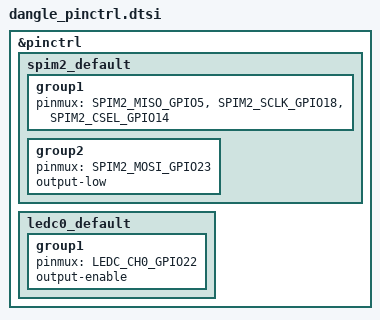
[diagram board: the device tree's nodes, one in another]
&pinctrl {
      spim2_default: spim2_default {
      		group1 {
      			pinmux = <SPIM2_MISO_GPIO5>,
      				 <SPIM2_SCLK_GPIO18>,
      				 <SPIM2_CSEL_GPIO14>;
      		};

      		group2 {
      			pinmux = <SPIM2_MOSI_GPIO23>;
      			output-low;
      		};

      	};

      	ledc0_default: ledc0_default {
      		group1 {
      			pinmux = <LEDC_CH0_GPIO22>;
      			output-enable;
      		};
      	};
};
